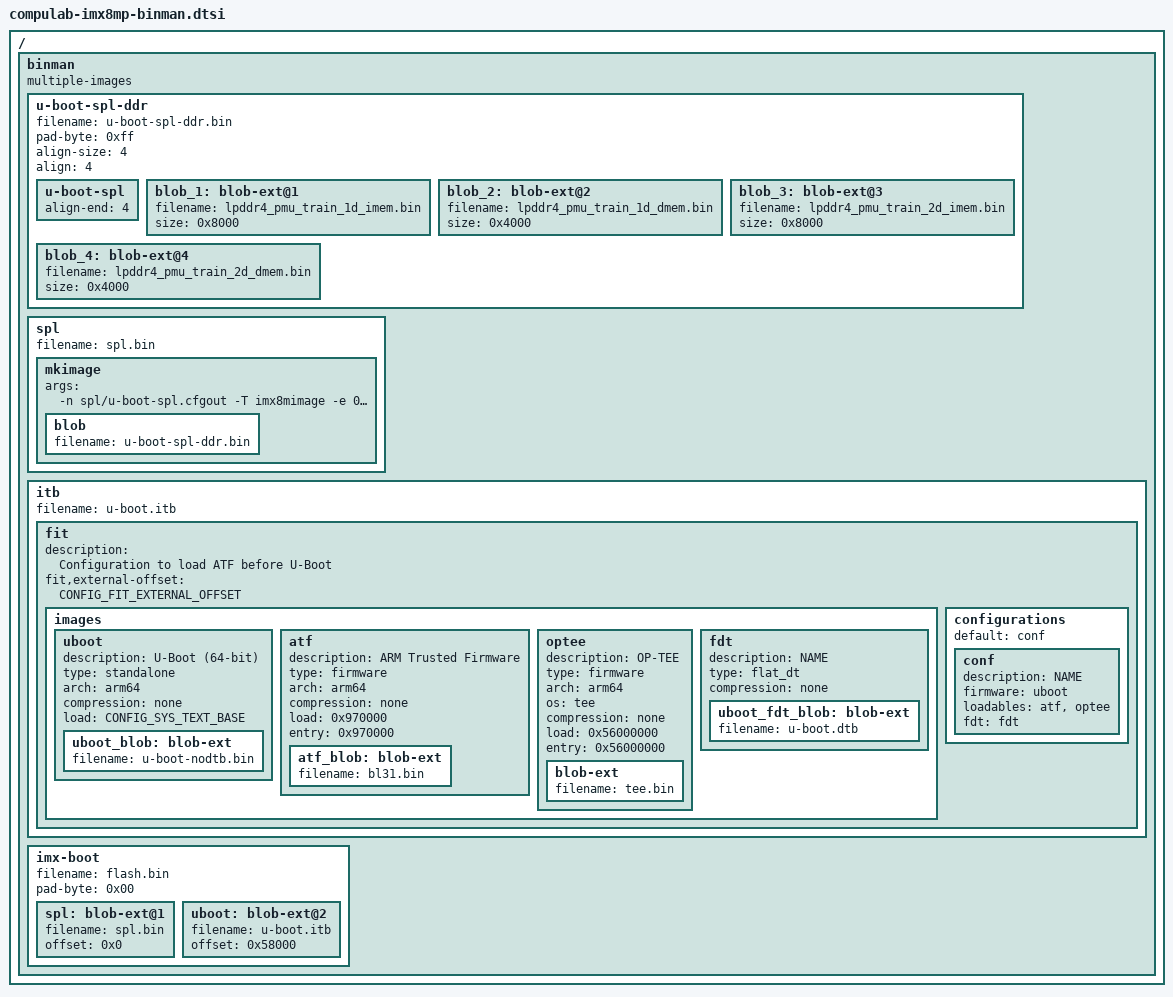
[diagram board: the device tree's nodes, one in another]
/ {
	binman: binman {
		multiple-images;
	};
};

&binman {
	 u-boot-spl-ddr {
		filename = "u-boot-spl-ddr.bin";
		pad-byte = <0xff>;
		align-size = <4>;
		align = <4>;

		u-boot-spl {
			align-end = <4>;
		};

		blob_1: blob-ext@1 {
			filename = "lpddr4_pmu_train_1d_imem.bin";
			size = <0x8000>;
		};

		blob_2: blob-ext@2 {
			filename = "lpddr4_pmu_train_1d_dmem.bin";
			size = <0x4000>;
		};

		blob_3: blob-ext@3 {
			filename = "lpddr4_pmu_train_2d_imem.bin";
			size = <0x8000>;
		};

		blob_4: blob-ext@4 {
			filename = "lpddr4_pmu_train_2d_dmem.bin";
			size = <0x4000>;
		};
	};

	spl {
		filename = "spl.bin";

		mkimage {
			args = "-n spl/u-boot-spl.cfgout -T imx8mimage -e 0x920000";

			blob {
				filename = "u-boot-spl-ddr.bin";
			};
		};
	};

	itb {
		filename = "u-boot.itb";

		fit {
			description = "Configuration to load ATF before U-Boot";
			#address-cells = <1>;
			fit,external-offset = <CONFIG_FIT_EXTERNAL_OFFSET>;

			images {
				uboot {
					description = "U-Boot (64-bit)";
					type = "standalone";
					arch = "arm64";
					compression = "none";
					load = <CONFIG_SYS_TEXT_BASE>;

					uboot_blob: blob-ext {
						filename = "u-boot-nodtb.bin";
					};
				};

				atf {
					description = "ARM Trusted Firmware";
					type = "firmware";
					arch = "arm64";
					compression = "none";
					load = <0x970000>;
					entry = <0x970000>;

					atf_blob: blob-ext {
						filename = "bl31.bin";
					};
				};

				optee {
					description = "OP-TEE";
					type = "firmware";
					arch = "arm64";
					os = "tee";
					compression = "none";
					load = <0x56000000>;
					entry = <0x56000000>;

					blob-ext {
						filename = "tee.bin";
					};
				};

				fdt {
					description = "NAME";
					type = "flat_dt";
					compression = "none";

					uboot_fdt_blob: blob-ext {
						filename = "u-boot.dtb";
					};
				};
			};

			configurations {
				default = "conf";

				conf {
					description = "NAME";
					firmware = "uboot";
					loadables = "atf" , "optee";
					fdt = "fdt";
				};
			};
		};
	};

	imx-boot {
		filename = "flash.bin";
		pad-byte = <0x00>;

		spl: blob-ext@1 {
			filename = "spl.bin";
			offset = <0x0>;
		};

		uboot: blob-ext@2 {
			filename = "u-boot.itb";
			offset = <0x58000>;
		};
	};
};
